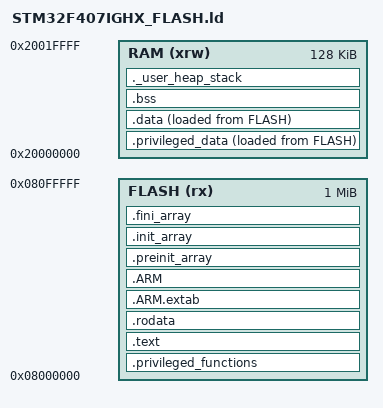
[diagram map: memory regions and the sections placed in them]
/*
******************************************************************************
**
** @file        : LinkerScript.ld
**
** @author      : Auto-generated by STM32CubeIDE
**
** @brief       : Linker script for STM32F407IGHx Device from STM32F4 series
**                      32Kbytes ROM_privileged
**                      4Kbytes ROM_system_calls
**                      988Kbytes ROM_unprivileged
**                      32Kbytes RAM_privileged
**                      96Kbytes RAM_unprivileged
**
**                Set heap size, stack size and stack location according
**                to application requirements.
**
**                Set memory bank area and size if external memory is used
**
**  Target      : STMicroelectronics STM32
**
**  Distribution: The file is distributed as is, without any warranty
**                of any kind.
**
******************************************************************************
** @attention
**
** Copyright (c) 2022 STMicroelectronics.
** All rights reserved.
**
** This software is licensed under terms that can be found in the LICENSE file
** in the root directory of this software component.
** If no LICENSE file comes with this software, it is provided AS-IS.
**
******************************************************************************
*/

/* Entry Point */
ENTRY(Reset_Handler)

_estack = ORIGIN(RAM) + LENGTH(RAM);	/* end of "RAM" Ram type memory */

_Min_Heap_Size = 0x200 ;	/* required amount of heap  */
_Min_Stack_Size = 0x400 ;	/* required amount of stack */

/* Memories definition */
MEMORY
{
  RAM	(xrw)	: ORIGIN = 0x20000000,	LENGTH = 128K
  FLASH	(rx)	: ORIGIN = 0x08000000,	LENGTH = 1024K
}

/* Initial 32K Flash is used to store kernel functions and
 * initial 32K RAM is used to store kernel data. */
__privileged_functions_region_size__  = 32K;
__privileged_data_region_size__       = 32K;

__FLASH_segment_start__               = ORIGIN( FLASH );
__FLASH_segment_end__                 = __FLASH_segment_start__ + LENGTH( FLASH );

__SRAM_segment_start__                = ORIGIN( RAM );
__SRAM_segment_end__                  = __SRAM_segment_start__ + LENGTH( RAM );

__privileged_functions_start__        = __FLASH_segment_start__;
__privileged_functions_end__          = __FLASH_segment_start__ + __privileged_functions_region_size__;

__privileged_data_start__             = __SRAM_segment_start__;
__privileged_data_end__               = __SRAM_segment_start__ + __privileged_data_region_size__;

/* Sections */
SECTIONS
{
  /* The startup code and FreeRTOS kernel code are placed into privileged
   * flash. */
  .privileged_functions :
  {
    . = ALIGN(4);
    KEEP(*(.isr_vector)) /* Startup code. */
    . = ALIGN(4);
    *(privileged_functions)
    . = ALIGN(4);
    FILL(0xDEAD);
    /* Ensure that non-privileged code is placed after the region reserved for
     * privileged kernel code. */
    /* Note that dot (.) actually refers to the byte offset from the start of
     * the current section (.privileged_functions in this case). As a result,
     * setting dot (.) to a value sets the size of the section. */
    . = __privileged_functions_region_size__;
  } >FLASH

  /* The program code and other data into "FLASH" Rom type memory */
  .text :
  {
    /* Place the FreeRTOS System Calls first in the unprivileged region. */
    . = ALIGN(4);
    __syscalls_flash_start__ = .;
    *(freertos_system_calls)
    __syscalls_flash_end__ = .;
    . = ALIGN(4);
    *(.text)           /* .text sections (code) */
    *(.text*)          /* .text* sections (code) */
    *(.glue_7)         /* glue arm to thumb code */
    *(.glue_7t)        /* glue thumb to arm code */
    *(.eh_frame)

    KEEP (*(.init))
    KEEP (*(.fini))

    . = ALIGN(4);
    _etext = .;        /* define a global symbols at end of code */
  } >FLASH

  /* Constant data into "FLASH" Rom type memory */
  .rodata :
  {
    . = ALIGN(4);
    *(.rodata)         /* .rodata sections (constants, strings, etc.) */
    *(.rodata*)        /* .rodata* sections (constants, strings, etc.) */
    . = ALIGN(4);
  } >FLASH

  .ARM.extab (READONLY) : /* The READONLY keyword is only supported in GCC11 and later, remove it if using GCC10 or earlier. */
  {
    . = ALIGN(4);
    *(.ARM.extab* .gnu.linkonce.armextab.*)
    . = ALIGN(4);
  } >FLASH

  .ARM (READONLY) : /* The READONLY keyword is only supported in GCC11 and later, remove it if using GCC10 or earlier. */
  {
    . = ALIGN(4);
    __exidx_start = .;
    *(.ARM.exidx*)
    __exidx_end = .;
    . = ALIGN(4);
  } >FLASH

  .preinit_array (READONLY) : /* The READONLY keyword is only supported in GCC11 and later, remove it if using GCC10 or earlier. */
  {
    . = ALIGN(4);
    PROVIDE_HIDDEN (__preinit_array_start = .);
    KEEP (*(.preinit_array*))
    PROVIDE_HIDDEN (__preinit_array_end = .);
    . = ALIGN(4);
  } >FLASH

  .init_array (READONLY) : /* The READONLY keyword is only supported in GCC11 and later, remove it if using GCC10 or earlier. */
  {
    . = ALIGN(4);
    PROVIDE_HIDDEN (__init_array_start = .);
    KEEP (*(SORT(.init_array.*)))
    KEEP (*(.init_array*))
    PROVIDE_HIDDEN (__init_array_end = .);
    . = ALIGN(4);
  } >FLASH

  .fini_array (READONLY) : /* The READONLY keyword is only supported in GCC11 and later, remove it if using GCC10 or earlier. */
  {
    . = ALIGN(4);
    PROVIDE_HIDDEN (__fini_array_start = .);
    KEEP (*(SORT(.fini_array.*)))
    KEEP (*(.fini_array*))
    PROVIDE_HIDDEN (__fini_array_end = .);
    . = ALIGN(4);
  } >FLASH

  /* Used by the startup to initialize data */
  _sidata = LOADADDR(.privileged_data);

  /* FreeRTOS kernel data. */
  .privileged_data :
  {
    . = ALIGN(4);
    _sdata = .;        /* Create a global symbol at data start. */
    *(privileged_data)
    . = ALIGN(4);
    FILL(0xDEAD);
    /* Ensure that non-privileged data is placed after the region reserved for
     * privileged kernel data. */
    /* Note that dot (.) actually refers to the byte offset from the start of
     * the current section (.privileged_data in this case). As a result, setting
     * dot (.) to a value sets the size of the section. */
    . = __privileged_data_region_size__;
  } >RAM AT> FLASH

  /* Initialized data sections into "RAM" Ram type memory */
  .data :
  {
    . = ALIGN(4);
    *(.data)           /* .data sections */
    *(.data*)          /* .data* sections */

    . = ALIGN(4);
    _edata = .;        /* define a global symbol at data end */

  } >RAM AT> FLASH

  /* Uninitialized data section into "RAM" Ram type memory */
  . = ALIGN(4);
  .bss :
  {
    /* This is used by the startup in order to initialize the .bss section */
    _sbss = .;         /* define a global symbol at bss start */
    __bss_start__ = _sbss;
    *(.bss)
    *(.bss*)
    *(COMMON)

    . = ALIGN(4);
    _ebss = .;         /* define a global symbol at bss end */
    __bss_end__ = _ebss;
  } >RAM

  /* User_heap_stack section, used to check that there is enough "RAM" Ram  type memory left */
  ._user_heap_stack :
  {
    . = ALIGN(8);
    PROVIDE ( end = . );
    PROVIDE ( _end = . );
    . = . + _Min_Heap_Size;
    . = . + _Min_Stack_Size;
    . = ALIGN(8);
  } >RAM

  /* Remove information from the compiler libraries */
  /DISCARD/ :
  {
    libc.a ( * )
    libm.a ( * )
    libgcc.a ( * )
  }

  .ARM.attributes 0 : { *(.ARM.attributes) }
}
